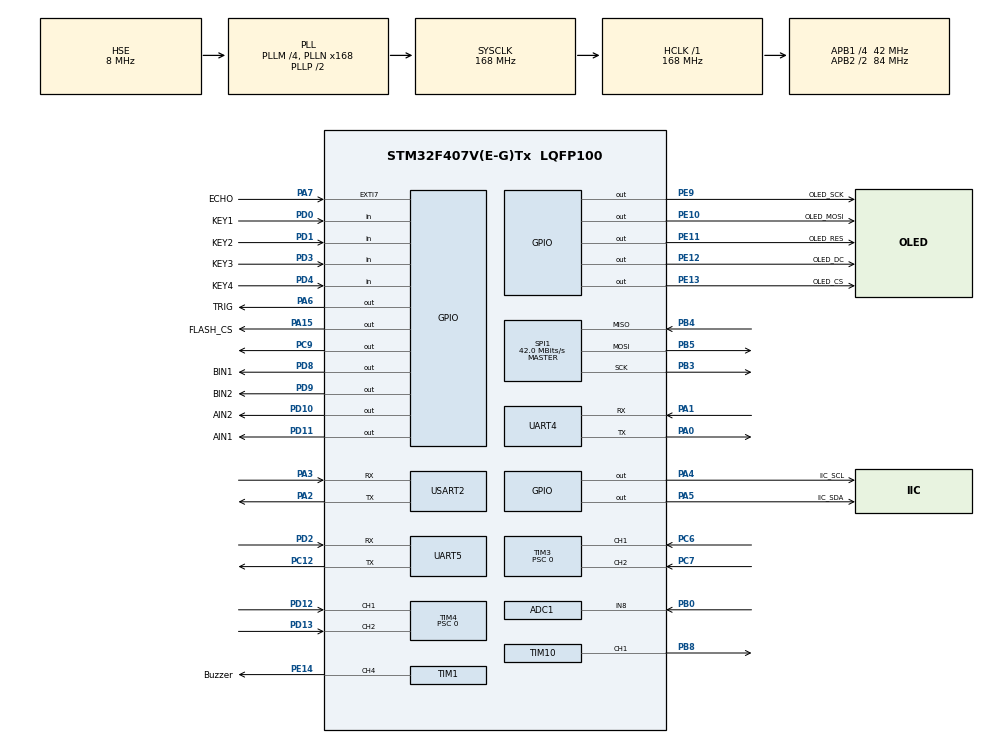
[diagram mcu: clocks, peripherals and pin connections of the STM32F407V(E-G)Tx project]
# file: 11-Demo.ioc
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ADC1.Channel-1\#ChannelRegularConversion=ADC_CHANNEL_8
ADC1.ContinuousConvMode=DISABLE
ADC1.NbrOfConversionFlag=1
ADC1.Rank-1\#ChannelRegularConversion=1
ADC1.SamplingTime-1\#ChannelRegularConversion=ADC_SAMPLETIME_3CYCLES
ADC1.master=1
Mcu.Family=STM32F4
Mcu.Name=STM32F407V(E-G)Tx
Mcu.Package=LQFP100
NVIC.EXTI9_5_IRQn=true\:2\:0\:false\:false\:true\:true\:true\:true
NVIC.PriorityGroup=NVIC_PRIORITYGROUP_4
NVIC.TIM2_IRQn=true\:4\:0\:false\:false\:true\:true\:true\:true
NVIC.TIM6_DAC_IRQn=true\:5\:0\:false\:false\:true\:true\:true\:true
NVIC.UART4_IRQn=true\:6\:0\:false\:false\:true\:true\:true\:true
NVIC.UART5_IRQn=true\:6\:0\:false\:false\:true\:true\:true\:true
NVIC.USART2_IRQn=true\:6\:0\:false\:false\:true\:true\:true\:true
PA0-WKUP.Mode=Asynchronous
PA0-WKUP.Signal=UART4_TX
PA1.Mode=Asynchronous
PA1.Signal=UART4_RX
PA13.Mode=Serial_Wire
PA13.Signal=SYS_JTMS-SWDIO
PA14.Mode=Serial_Wire
PA14.Signal=SYS_JTCK-SWCLK
PA15.GPIO_Label=FLASH_CS
PA15.PinState=GPIO_PIN_SET
PA15.Signal=GPIO_Output
PA2.Mode=Asynchronous
PA2.Signal=USART2_TX
PA3.Mode=Asynchronous
PA3.Signal=USART2_RX
PA4.GPIO_Label=IIC_SCL
PA4.GPIO_ModeDefaultOutputPP=GPIO_MODE_OUTPUT_OD
PA4.GPIO_PuPd=GPIO_PULLUP
PA4.GPIO_Speed=GPIO_SPEED_FREQ_MEDIUM
PA4.PinState=GPIO_PIN_SET
PA4.Signal=GPIO_Output
PA5.GPIO_Label=IIC_SDA
PA5.GPIO_ModeDefaultOutputPP=GPIO_MODE_OUTPUT_OD
PA5.GPIO_PuPd=GPIO_PULLUP
PA5.GPIO_Speed=GPIO_SPEED_FREQ_MEDIUM
PA5.PinState=GPIO_PIN_SET
PA5.Signal=GPIO_Output
PA6.GPIO_Label=TRIG
PA6.GPIO_Speed=GPIO_SPEED_FREQ_MEDIUM
PA6.Signal=GPIO_Output
PA7.GPIO_Label=ECHO
PA7.GPIO_ModeDefaultEXTI=GPIO_MODE_IT_RISING_FALLING
PA7.GPIO_PuPd=GPIO_PULLDOWN
PA7.Signal=GPXTI7
PB0.Signal=ADCx_IN8
PB3.Mode=Full_Duplex_Master
PB3.Signal=SPI1_SCK
PB4.Mode=Full_Duplex_Master
PB4.Signal=SPI1_MISO
PB5.Mode=Full_Duplex_Master
PB5.Signal=SPI1_MOSI
PB8.GPIO_Speed=GPIO_SPEED_FREQ_HIGH
PB8.Signal=S_TIM10_CH1
PC12.Mode=Asynchronous
PC12.Signal=UART5_TX
PC6.GPIO_PuPd=GPIO_PULLUP
PC6.Signal=S_TIM3_CH1
PC7.GPIO_PuPd=GPIO_PULLUP
PC7.Signal=S_TIM3_CH2
PC9.Signal=GPIO_Output
PD0.GPIO_Label=KEY1
PD0.GPIO_PuPd=GPIO_PULLUP
PD0.Signal=GPIO_Input
PD1.GPIO_Label=KEY2
PD1.GPIO_PuPd=GPIO_PULLUP
PD1.Signal=GPIO_Input
PD10.GPIO_Label=AIN2
PD10.GPIO_Speed=GPIO_SPEED_FREQ_MEDIUM
PD10.PinState=GPIO_PIN_SET
PD10.Signal=GPIO_Output
PD11.GPIO_Label=AIN1
PD11.GPIO_Speed=GPIO_SPEED_FREQ_MEDIUM
PD11.PinState=GPIO_PIN_SET
PD11.Signal=GPIO_Output
PD12.GPIO_PuPd=GPIO_PULLUP
PD12.Signal=S_TIM4_CH1
PD13.GPIO_PuPd=GPIO_PULLUP
PD13.Signal=S_TIM4_CH2
PD2.Mode=Asynchronous
PD2.Signal=UART5_RX
PD3.GPIO_Label=KEY3
PD3.GPIO_PuPd=GPIO_PULLUP
PD3.Signal=GPIO_Input
PD4.GPIO_Label=KEY4
PD4.GPIO_PuPd=GPIO_PULLUP
PD4.Signal=GPIO_Input
PD8.GPIO_Label=BIN1
PD8.GPIO_Speed=GPIO_SPEED_FREQ_MEDIUM
PD8.PinState=GPIO_PIN_SET
PD8.Signal=GPIO_Output
PD9.GPIO_Label=BIN2
PD9.GPIO_Speed=GPIO_SPEED_FREQ_MEDIUM
PD9.PinState=GPIO_PIN_SET
PD9.Signal=GPIO_Output
PE10.GPIO_Label=OLED_MOSI
PE10.GPIO_Speed=GPIO_SPEED_FREQ_MEDIUM
PE10.Signal=GPIO_Output
PE11.GPIO_Label=OLED_RES
PE11.GPIO_Speed=GPIO_SPEED_FREQ_MEDIUM
PE11.Signal=GPIO_Output
PE12.GPIO_Label=OLED_DC
PE12.GPIO_Speed=GPIO_SPEED_FREQ_MEDIUM
PE12.Signal=GPIO_Output
PE13.GPIO_Label=OLED_CS
PE13.GPIO_Speed=GPIO_SPEED_FREQ_MEDIUM
PE13.Signal=GPIO_Output
PE14.GPIO_Label=Buzzer
PE14.GPIO_Speed=GPIO_SPEED_FREQ_LOW
PE14.Signal=S_TIM1_CH4
PE9.GPIO_Label=OLED_SCK
PE9.GPIO_Speed=GPIO_SPEED_FREQ_MEDIUM
PE9.Signal=GPIO_Output
PH0-OSC_IN.Mode=HSE-External-Oscillator
PH0-OSC_IN.Signal=RCC_OSC_IN
PH1-OSC_OUT.Mode=HSE-External-Oscillator
PH1-OSC_OUT.Signal=RCC_OSC_OUT
ProjectManager.HeapSize=0x200
ProjectManager.StackSize=0x1000
ProjectManager.TargetToolchain=MDK-ARM V5.32
RCC.48MHZClocksFreq_Value=48000000
RCC.AHBFreq_Value=168000000
RCC.APB1CLKDivider=RCC_HCLK_DIV4
RCC.APB1Freq_Value=42000000
RCC.APB1TimFreq_Value=84000000
RCC.APB2CLKDivider=RCC_HCLK_DIV2
RCC.APB2Freq_Value=84000000
RCC.APB2TimFreq_Value=168000000
RCC.CortexFreq_Value=168000000
RCC.HCLKFreq_Value=168000000
RCC.HSE_VALUE=8000000
RCC.HSI_VALUE=16000000
RCC.LSE_VALUE=32768
RCC.PLLM=4
RCC.PLLN=168
RCC.PLLQ=7
RCC.PLLSourceVirtual=RCC_PLLSOURCE_HSE
RCC.RTCHSEDivValue=8
RCC.SYSCLKFreq_VALUE=168000000
RCC.SYSCLKSource=RCC_SYSCLKSOURCE_PLLCLK
RCC.VCOOutputFreq_Value=336000000
SH.ADCx_IN8.0=ADC1_IN8,IN8
SH.S_TIM10_CH1.0=TIM10_CH1,PWM Generation1 CH1
SH.S_TIM1_CH4.0=TIM1_CH4,PWM Generation4 CH4
SH.S_TIM3_CH1.0=TIM3_CH1,Encoder_Interface
SH.S_TIM3_CH2.0=TIM3_CH2,Encoder_Interface
SH.S_TIM4_CH1.0=TIM4_CH1,Encoder_Interface
SH.S_TIM4_CH2.0=TIM4_CH2,Encoder_Interface
SPI1.CalculateBaudRate=42.0 MBits/s
SPI1.Direction=SPI_DIRECTION_2LINES
SPI1.Mode=SPI_MODE_MASTER
SPI1.VirtualType=VM_MASTER
TIM1.Channel-PWM\ Generation4\ CH4=TIM_CHANNEL_4
TIM1.Period=731
TIM1.Prescaler=83
TIM10.Channel=TIM_CHANNEL_1
TIM10.Period=209
TIM2.Period=8399
TIM2.Prescaler=0
TIM3.EncoderMode=TIM_ENCODERMODE_TI12
TIM3.IC1Filter=6
TIM3.IC2Filter=6
TIM3.Period=65535
TIM3.Prescaler=0
TIM4.EncoderMode=TIM_ENCODERMODE_TI12
TIM4.IC1Filter=6
TIM4.IC2Filter=6
TIM4.Period=65535
TIM4.Prescaler=0
TIM5.Period=4294967295
TIM5.Prescaler=83
TIM6.Period=9999
TIM6.Prescaler=83
UART4.VirtualMode=Asynchronous
UART5.VirtualMode=Asynchronous
USART2.VirtualMode=VM_ASYNC
VP_TIM10_VS_ClockSourceINT.Mode=Enable_Timer
VP_TIM1_VS_ClockSourceINT.Mode=Internal
VP_TIM2_VS_ClockSourceINT.Mode=Internal
VP_TIM5_VS_ClockSourceINT.Mode=Internal
VP_TIM6_VS_ClockSourceINT.Mode=Enable_Timer
board=custom

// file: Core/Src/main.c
/* USER CODE BEGIN Header */
/**
  ******************************************************************************
  * @file           : main.c
  * @brief          : Main program body
  ******************************************************************************
  * @attention
  *
  * Copyright (c) 2025 STMicroelectronics.
  * All rights reserved.
  *
  * This software is licensed under terms that can be found in the LICENSE file
  * in the root directory of this software component.
  * If no LICENSE file comes with this software, it is provided AS-IS.
  *
  ******************************************************************************
  */
/* USER CODE END Header */
#include "main.h"
#include "adc.h"
#include "spi.h"
#include "tim.h"
#include "usart.h"
#include "gpio.h"

/* USER CODE BEGIN Includes */
#include "demo_app.h"
#include "motor_pwm.h"
#include "usart.h"
#include "spi.h"
/* USER CODE END Includes */

void SystemClock_Config(void);

int main(void)
{

  /* MCU Configuration--------------------------------------------------------*/

  /* Reset of all peripherals, Initializes the Flash interface and the Systick. */
  HAL_Init();

  /* Configure the system clock */
  SystemClock_Config();

  /* Initialize all configured peripherals */
  MX_GPIO_Init();
  MX_ADC1_Init();
  MX_TIM3_Init();
  MX_TIM1_Init();
  MX_TIM2_Init();
  MX_TIM4_Init();
  MX_TIM5_Init();
  MX_TIM6_Init();
  MX_TIM10_Init();
  MX_UART4_Init();
  MX_USART2_UART_Init();
  MX_UART5_Init();
  MX_SPI1_Init();
  /* USER CODE BEGIN 2 */
  Demo_Init();
  /* USER CODE END 2 */

  /* Infinite loop */
  while (1)
  {

    /* USER CODE BEGIN 3 */
    Demo_Task();
    HAL_Delay(1U);
  }
  /* USER CODE END 3 */
}

void SystemClock_Config(void)
{
  RCC_OscInitTypeDef RCC_OscInitStruct = {0};
  RCC_ClkInitTypeDef RCC_ClkInitStruct = {0};

  /** Configure the main internal regulator output voltage
  */
  __HAL_RCC_PWR_CLK_ENABLE();
  __HAL_PWR_VOLTAGESCALING_CONFIG(PWR_REGULATOR_VOLTAGE_SCALE1);

  /** Initializes the RCC Oscillators according to the specified parameters
  * in the RCC_OscInitTypeDef structure.
  */
  RCC_OscInitStruct.OscillatorType = RCC_OSCILLATORTYPE_HSE;
  RCC_OscInitStruct.HSEState = RCC_HSE_ON;
  RCC_OscInitStruct.PLL.PLLState = RCC_PLL_ON;
  RCC_OscInitStruct.PLL.PLLSource = RCC_PLLSOURCE_HSE;
  RCC_OscInitStruct.PLL.PLLM = 4;
  RCC_OscInitStruct.PLL.PLLN = 168;
  RCC_OscInitStruct.PLL.PLLP = RCC_PLLP_DIV2;
  RCC_OscInitStruct.PLL.PLLQ = 7;
  if (HAL_RCC_OscConfig(&RCC_OscInitStruct) != HAL_OK)
  {
    Error_Handler();
  }

  /** Initializes the CPU, AHB and APB buses clocks
  */
  RCC_ClkInitStruct.ClockType = RCC_CLOCKTYPE_HCLK|RCC_CLOCKTYPE_SYSCLK
                              |RCC_CLOCKTYPE_PCLK1|RCC_CLOCKTYPE_PCLK2;
  RCC_ClkInitStruct.SYSCLKSource = RCC_SYSCLKSOURCE_PLLCLK;
  RCC_ClkInitStruct.AHBCLKDivider = RCC_SYSCLK_DIV1;
  RCC_ClkInitStruct.APB1CLKDivider = RCC_HCLK_DIV4;
  RCC_ClkInitStruct.APB2CLKDivider = RCC_HCLK_DIV2;

  if (HAL_RCC_ClockConfig(&RCC_ClkInitStruct, FLASH_LATENCY_5) != HAL_OK)
  {
    Error_Handler();
  }
}

void Error_Handler(void)
{
  /* USER CODE BEGIN Error_Handler_Debug */
  /* User can add his own implementation to report the HAL error return state */
  __disable_irq();
  motor_pwm_emergency_stop();
  while (1)
  {
  }
  /* USER CODE END Error_Handler_Debug */
}
